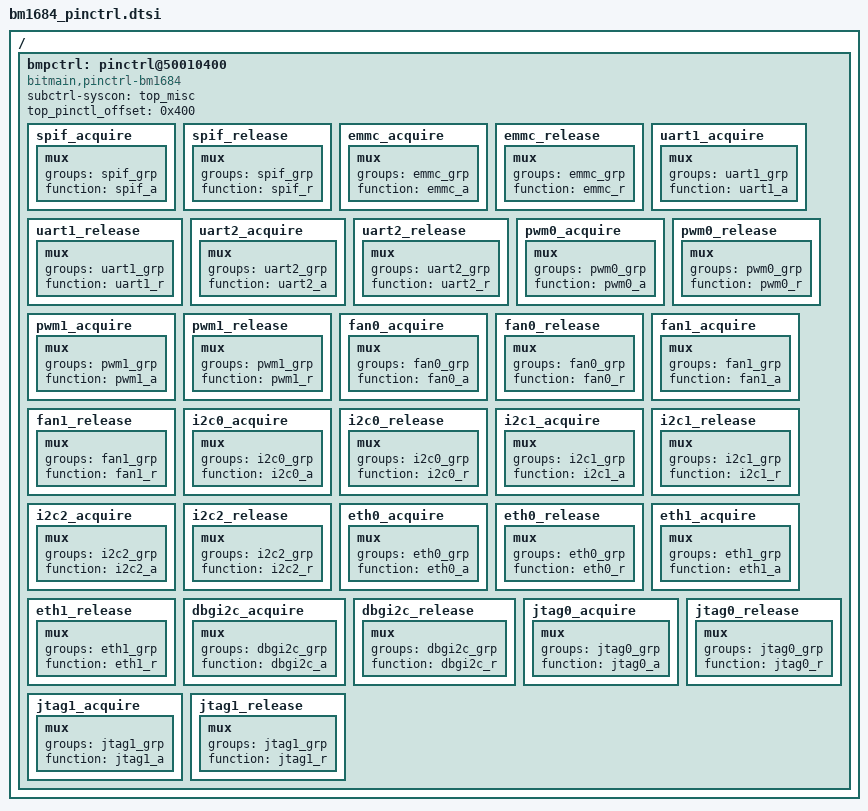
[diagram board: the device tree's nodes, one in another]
/ {
	bmpctrl: pinctrl@50010400 {
		compatible = "bitmain,pinctrl-bm1684";
		subctrl-syscon = <&top_misc>;
		top_pinctl_offset = <0x400>;

		spif_acquire: spif_acquire {
			mux {
				groups = "spif_grp";
				function = "spif_a";
			};
		};

		spif_release: spif_release{
			mux {
				groups = "spif_grp";
				function = "spif_r";
			};
		};

		emmc_acquire: emmc_acquire {
			mux {
				groups = "emmc_grp";
				function = "emmc_a";
			};
		};

		emmc_release: emmc_release{
			mux {
				groups = "emmc_grp";
				function = "emmc_r";
			};
		};

		uart1_acquire: uart1_acquire {
			mux {
				groups = "uart1_grp";
				function = "uart1_a";
			};
		};

		uart1_release: uart1_release{
			mux {
				groups = "uart1_grp";
				function = "uart1_r";
			};
		};

		uart2_acquire: uart2_acquire {
			mux {
				groups = "uart2_grp";
				function = "uart2_a";
			};
		};

		uart2_release: uart2_release{
			mux {
				groups = "uart2_grp";
				function = "uart2_r";
			};
		};

		pwm0_acquire: pwm0_acquire {
			mux {
				groups = "pwm0_grp";
				function = "pwm0_a";
			};
		};

		pwm0_release: pwm0_release{
			mux {
				groups = "pwm0_grp";
				function = "pwm0_r";
			};
		};

		pwm1_acquire: pwm1_acquire {
			mux {
				groups = "pwm1_grp";
				function = "pwm1_a";
			};
		};

		pwm1_release: pwm1_release{
			mux {
			groups = "pwm1_grp";
			function = "pwm1_r";
			};
		};

		fan0_acquire: fan0_acquire {
			mux {
			groups = "fan0_grp";
			function = "fan0_a";
			};
		};

		fan0_release: fan0_release{
			mux {
			groups = "fan0_grp";
			function = "fan0_r";
			};
		};

		fan1_acquire: fan1_acquire {
			mux {
			groups = "fan1_grp";
			function = "fan1_a";
			};
		};

		fan1_release: fan1_release{
			mux {
			groups = "fan1_grp";
			function = "fan1_r";
			};
		};

		i2c0_acquire: i2c0_acquire {
			mux {
				groups = "i2c0_grp";
				function = "i2c0_a";
			};
		};

		i2c0_release: i2c0_release{
			mux {
				groups = "i2c0_grp";
				function = "i2c0_r";
			};
		};

		i2c1_acquire: i2c1_acquire {
			mux {
				groups = "i2c1_grp";
				function = "i2c1_a";
			};
		};

		i2c1_release: i2c1_release{
			mux {
				groups = "i2c1_grp";
				function = "i2c1_r";
			};
		};

		i2c2_acquire: i2c2_acquire {
			mux {
				groups = "i2c2_grp";
				function = "i2c2_a";
			};
		};

		i2c2_release: i2c2_release{
			mux {
				groups = "i2c2_grp";
				function = "i2c2_r";
			};
		};

		eth0_acquire: eth0_acquire {
			mux {
				groups = "eth0_grp";
				function = "eth0_a";
			};
		};

		eth0_release: eth0_release{
			mux {
				groups = "eth0_grp";
				function = "eth0_r";
			};
		};

		eth1_acquire: eth1_acquire {
			mux {
				groups = "eth1_grp";
				function = "eth1_a";
			};
		};

		eth1_release: eth1_release{
			mux {
				groups = "eth1_grp";
				function = "eth1_r";
			};
		};

		dbgi2c_acquire: dbgi2c_acquire {
			mux {
				groups = "dbgi2c_grp";
				function = "dbgi2c_a";
			};
		};

		dbgi2c_release: dbgi2c_release{
			mux {
				groups = "dbgi2c_grp";
				function = "dbgi2c_r";
			};
		};

		jtag0_acquire: jtag0_acquire {
			mux {
				groups = "jtag0_grp";
				function = "jtag0_a";
			};
		};

		jtag0_release: jtag0_release{
			mux {
				groups = "jtag0_grp";
				function = "jtag0_r";
			};
		};

		jtag1_acquire: jtag1_acquire {
			mux {
				groups = "jtag1_grp";
				function = "jtag1_a";
			};
		};

		jtag1_release: jtag1_release{
			mux {
				groups = "jtag1_grp";
				function = "jtag1_r";
			};
		};
	};
};
